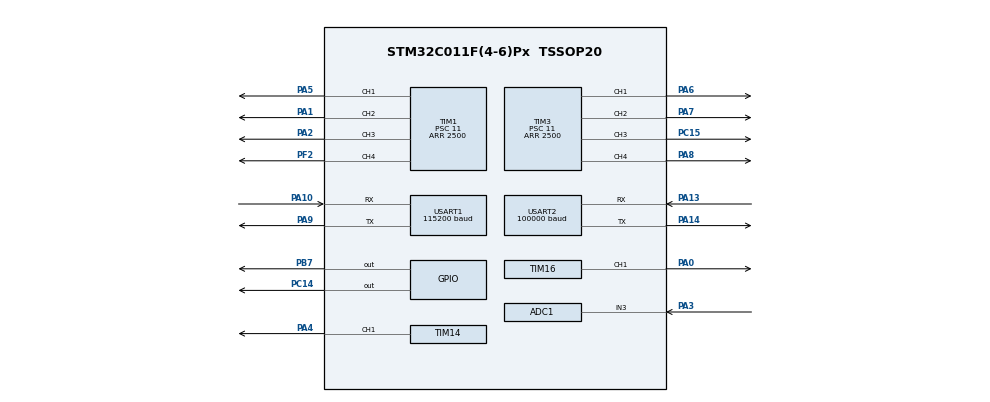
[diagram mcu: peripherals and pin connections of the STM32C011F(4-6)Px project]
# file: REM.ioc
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ADC1.Channel-0\#ChannelRegularConversion=ADC_CHANNEL_3
ADC1.ClockPrescaler=ADC_CLOCK_ASYNC_DIV4
ADC1.ContinuousConvMode=ENABLE
ADC1.DMAContinuousRequests=ENABLE
ADC1.NbrOfConversion=1
ADC1.NbrOfConversionFlag=1
ADC1.Rank-0\#ChannelRegularConversion=1
ADC1.Resolution=ADC_RESOLUTION_8B
ADC1.SamplingTime-0\#ChannelRegularConversion=ADC_SAMPLINGTIME_COMMON_1
ADC1.SamplingTimeCommon1=ADC_SAMPLETIME_79CYCLES_5
ADC1.SelectedChannel=ADC_CHANNEL_3
ADC1.Sequencer=FULLY_CONFIGURABLE
ADC1.TriggerFrequencyMode=ADC_TRIGGER_FREQ_LOW
ADC1.master=1
Dma.ADC1.1.Direction=DMA_PERIPH_TO_MEMORY
Dma.ADC1.1.EventEnable=DISABLE
Dma.ADC1.1.Instance=DMA1_Channel2
Dma.ADC1.1.MemDataAlignment=DMA_MDATAALIGN_HALFWORD
Dma.ADC1.1.MemInc=DMA_MINC_ENABLE
Dma.ADC1.1.Mode=DMA_CIRCULAR
Dma.ADC1.1.PeriphDataAlignment=DMA_PDATAALIGN_HALFWORD
Dma.ADC1.1.PeriphInc=DMA_PINC_DISABLE
Dma.ADC1.1.Polarity=HAL_DMAMUX_REQ_GEN_RISING
Dma.ADC1.1.Priority=DMA_PRIORITY_VERY_HIGH
Dma.ADC1.1.RequestNumber=1
Dma.ADC1.1.SignalID=NONE
Dma.ADC1.1.SyncEnable=DISABLE
Dma.ADC1.1.SyncPolarity=HAL_DMAMUX_SYNC_NO_EVENT
Dma.ADC1.1.SyncRequestNumber=1
Dma.ADC1.1.SyncSignalID=NONE
Dma.Request0=USART2_RX
Dma.Request1=ADC1
Dma.USART2_RX.0.Direction=DMA_PERIPH_TO_MEMORY
Dma.USART2_RX.0.EventEnable=DISABLE
Dma.USART2_RX.0.Instance=DMA1_Channel1
Dma.USART2_RX.0.MemDataAlignment=DMA_MDATAALIGN_BYTE
Dma.USART2_RX.0.MemInc=DMA_MINC_ENABLE
Dma.USART2_RX.0.Mode=DMA_NORMAL
Dma.USART2_RX.0.PeriphDataAlignment=DMA_PDATAALIGN_BYTE
Dma.USART2_RX.0.PeriphInc=DMA_PINC_DISABLE
Dma.USART2_RX.0.Polarity=HAL_DMAMUX_REQ_GEN_RISING
Dma.USART2_RX.0.Priority=DMA_PRIORITY_HIGH
Dma.USART2_RX.0.RequestNumber=1
Dma.USART2_RX.0.SignalID=NONE
Dma.USART2_RX.0.SyncEnable=DISABLE
Dma.USART2_RX.0.SyncPolarity=HAL_DMAMUX_SYNC_NO_EVENT
Dma.USART2_RX.0.SyncRequestNumber=1
Dma.USART2_RX.0.SyncSignalID=NONE
Mcu.Family=STM32C0
Mcu.Name=STM32C011F(4-6)Px
Mcu.Package=TSSOP20
NVIC.DMA1_Channel1_IRQn=true\:1\:0\:true\:false\:true\:false\:true\:true
NVIC.DMA1_Channel2_3_IRQn=true\:0\:0\:false\:false\:true\:false\:true\:true
NVIC.TIM17_IRQn=true\:0\:0\:true\:false\:true\:true\:true\:true
NVIC.USART2_IRQn=true\:1\:0\:true\:false\:true\:true\:true\:true
PA0.Signal=S_TIM16_CH1
PA1.GPIO_ModeDefaultPP=GPIO_MODE_AF_PP
PA1.GPIO_PuPd=GPIO_NOPULL
PA1.GPIO_Speed=GPIO_SPEED_FREQ_LOW
PA1.PinState=GPIO_PIN_RESET
PA1.Signal=S_TIM1_CH2
PA10\ [PA12].Mode=Asynchronous
PA10\ [PA12].Signal=USART1_RX
PA13.Mode=Asynchronous
PA13.Signal=USART2_RX
PA14-BOOT0.Mode=Asynchronous
PA14-BOOT0.Signal=USART2_TX
PA2.Signal=S_TIM1_CH3
PA3.Mode=IN3
PA3.Signal=ADC1_IN3
PA4.Signal=S_TIM14_CH1
PA5.Signal=S_TIM1_CH1
PA6.Signal=S_TIM3_CH1
PA7.Signal=S_TIM3_CH2
PA8.Signal=S_TIM3_CH4
PA9\ [PA11].Mode=Asynchronous
PA9\ [PA11].Signal=USART1_TX
PB7.Signal=GPIO_Output
PC14-OSCX_IN\ (PC14).Signal=GPIO_Output
PC15-OSCX_OUT\ (PC15).Signal=S_TIM3_CH3
PF2-NRST.Signal=S_TIM1_CH4
ProjectManager.HeapSize=0x200
ProjectManager.StackSize=0x400
ProjectManager.TargetToolchain=STM32CubeIDE
RCC.ADCFreq_Value=48000000
RCC.AHBCLKDivider=RCC_HCLK_DIV4
RCC.AHBFreq_Value=12000000
RCC.CortexFreq_Value=12000000
RCC.EXTERNAL_CLOCK_VALUE=12288000
RCC.HCLKFreq_Value=12000000
RCC.HSE_VALUE=8000000
RCC.HSISYSCLKDivider=RCC_HSI_DIV1
RCC.HSI_VALUE=48000000
RCC.LSE_VALUE=32768
RCC.SYSCLKFreq_VALUE=48000000
SH.S_TIM14_CH1.0=TIM14_CH1,PWM Generation1 CH1
SH.S_TIM16_CH1.0=TIM16_CH1,PWM Generation1 CH1
SH.S_TIM1_CH1.0=TIM1_CH1,PWM Generation1 CH1
SH.S_TIM1_CH2.0=TIM1_CH2,PWM Generation2 CH2
SH.S_TIM1_CH3.0=TIM1_CH3,PWM Generation3 CH3
SH.S_TIM1_CH4.0=TIM1_CH4,PWM Generation4 CH4
SH.S_TIM3_CH1.0=TIM3_CH1,PWM Generation1 CH1
SH.S_TIM3_CH2.0=TIM3_CH2,PWM Generation2 CH2
SH.S_TIM3_CH3.0=TIM3_CH3,PWM Generation3 CH3
SH.S_TIM3_CH4.0=TIM3_CH4,PWM Generation4 CH4
TIM1.Channel-PWM\ Generation1\ CH1=TIM_CHANNEL_1
TIM1.Channel-PWM\ Generation2\ CH2=TIM_CHANNEL_2
TIM1.Channel-PWM\ Generation3\ CH3=TIM_CHANNEL_3
TIM1.Channel-PWM\ Generation4\ CH4=TIM_CHANNEL_4
TIM1.OCMode_PWM-PWM\ Generation1\ CH1=TIM_OCMODE_PWM1
TIM1.OCMode_PWM-PWM\ Generation2\ CH2=TIM_OCMODE_PWM1
TIM1.OCMode_PWM-PWM\ Generation3\ CH3=TIM_OCMODE_PWM1
TIM1.OCMode_PWM-PWM\ Generation4\ CH4=TIM_OCMODE_PWM1
TIM1.Period=2500
TIM1.Prescaler=11
TIM1.Pulse-PWM\ Generation1\ CH1=0
TIM1.Pulse-PWM\ Generation2\ CH2=0
TIM1.Pulse-PWM\ Generation3\ CH3=0
TIM1.Pulse-PWM\ Generation4\ CH4=0
TIM14.Channel=TIM_CHANNEL_1
TIM14.OCMode_PWM=TIM_OCMODE_PWM1
TIM14.Period=2500
TIM14.Prescaler=11
TIM14.Pulse=0
TIM16.Channel=TIM_CHANNEL_1
TIM16.OCMode_PWM=TIM_OCMODE_PWM1
TIM16.Period=2500
TIM16.Prescaler=11
TIM16.Pulse=0
TIM17.Channel=TIM_CHANNEL_1
TIM17.Period=1000
TIM17.Prescaler=11999
TIM17.Pulse=500
TIM3.Channel-PWM\ Generation1\ CH1=TIM_CHANNEL_1
TIM3.Channel-PWM\ Generation2\ CH2=TIM_CHANNEL_2
TIM3.Channel-PWM\ Generation3\ CH3=TIM_CHANNEL_3
TIM3.Channel-PWM\ Generation4\ CH4=TIM_CHANNEL_4
TIM3.OCMode_PWM-PWM\ Generation1\ CH1=TIM_OCMODE_PWM2
TIM3.OCMode_PWM-PWM\ Generation2\ CH2=TIM_OCMODE_PWM2
TIM3.OCMode_PWM-PWM\ Generation3\ CH3=TIM_OCMODE_PWM1
TIM3.OCMode_PWM-PWM\ Generation4\ CH4=TIM_OCMODE_PWM2
TIM3.Period=2500
TIM3.Prescaler=11
TIM3.Pulse-PWM\ Generation1\ CH1=0
TIM3.Pulse-PWM\ Generation2\ CH2=0
TIM3.Pulse-PWM\ Generation3\ CH3=0
TIM3.Pulse-PWM\ Generation4\ CH4=0
USART1.BaudRate=115200
USART1.VirtualMode-Asynchronous=VM_ASYNC
USART2.BaudRate=100000
USART2.Parity=PARITY_EVEN
USART2.RxPinLevelInvertParam=ADVFEATURE_RXINV_ENABLE
USART2.StopBits=STOPBITS_2
USART2.VirtualMode-Asynchronous=VM_ASYNC
USART2.WordLength=WORDLENGTH_9B
VP_SYS_VS_PINREMAP.Mode=PINREMAP
VP_SYS_VS_PINREMAP_10_12.Mode=PINREMAP_10_12
VP_TIM14_VS_ClockSourceINT.Mode=Enable_Timer
VP_TIM16_VS_ClockSourceINT.Mode=Enable_Timer
VP_TIM17_VS_ClockSourceINT.Mode=Enable_Timer
VP_TIM17_VS_no_output1.Mode=PWM Generation1 No Output
VP_TIM1_VS_ClockSourceINT.Mode=Internal
VP_TIM3_VS_ClockSourceINT.Mode=Internal
board=custom

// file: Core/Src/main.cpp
/* USER CODE BEGIN Header */
/**
  ******************************************************************************
  * @file           : main.c
  * @brief          : Main program body
  ******************************************************************************
  * @attention
  *
  * Copyright (c) 2024 STMicroelectronics.
  * All rights reserved.
  *
  * This software is licensed under terms that can be found in the LICENSE file
  * in the root directory of this software component.
  * If no LICENSE file comes with this software, it is provided AS-IS.
  *
  ******************************************************************************
  */
/* USER CODE END Header */
#include "main.h"
#include "adc.h"
#include "dma.h"
#include "tim.h"
#include "usart.h"
#include "gpio.h"

/* USER CODE BEGIN Includes */
#include "wrapper.hpp"
/* USER CODE END Includes */

void SystemClock_Config(void);

int main(void)
{

  /* MCU Configuration--------------------------------------------------------*/

  /* Reset of all peripherals, Initializes the Flash interface and the Systick. */
  HAL_Init();

  /* Configure the system clock */
  SystemClock_Config();

  /* Initialize all configured peripherals */
  MX_GPIO_Init();
  MX_DMA_Init();
  MX_TIM1_Init();
  MX_TIM3_Init();
  MX_TIM14_Init();
  MX_TIM16_Init();
  MX_TIM17_Init();
  MX_USART2_UART_Init();
  MX_USART1_UART_Init();
  MX_ADC1_Init();
  /* USER CODE BEGIN 2 */
init();
  /* USER CODE END 2 */

  /* Infinite loop */
  /* USER CODE BEGIN WHILE */
  while (1)
  {
	  loop();
    /* USER CODE END WHILE */

  }
}

void SystemClock_Config(void)
{
  RCC_OscInitTypeDef RCC_OscInitStruct = {0};
  RCC_ClkInitTypeDef RCC_ClkInitStruct = {0};

  /** Initializes the RCC Oscillators according to the specified parameters
  * in the RCC_OscInitTypeDef structure.
  */
  RCC_OscInitStruct.OscillatorType = RCC_OSCILLATORTYPE_HSI;
  RCC_OscInitStruct.HSIState = RCC_HSI_ON;
  RCC_OscInitStruct.HSIDiv = RCC_HSI_DIV1;
  RCC_OscInitStruct.HSICalibrationValue = RCC_HSICALIBRATION_DEFAULT;
  if (HAL_RCC_OscConfig(&RCC_OscInitStruct) != HAL_OK)
  {
    Error_Handler();
  }

  /** Initializes the CPU, AHB and APB buses clocks
  */
  RCC_ClkInitStruct.ClockType = RCC_CLOCKTYPE_HCLK|RCC_CLOCKTYPE_SYSCLK
                              |RCC_CLOCKTYPE_PCLK1;
  RCC_ClkInitStruct.SYSCLKSource = RCC_SYSCLKSOURCE_HSI;
  RCC_ClkInitStruct.SYSCLKDivider = RCC_SYSCLK_DIV1;
  RCC_ClkInitStruct.AHBCLKDivider = RCC_HCLK_DIV4;
  RCC_ClkInitStruct.APB1CLKDivider = RCC_APB1_DIV1;

  if (HAL_RCC_ClockConfig(&RCC_ClkInitStruct, FLASH_LATENCY_0) != HAL_OK)
  {
    Error_Handler();
  }
}

void Error_Handler(void)
{
  __disable_irq();
  while (1)
  {
  }
}
